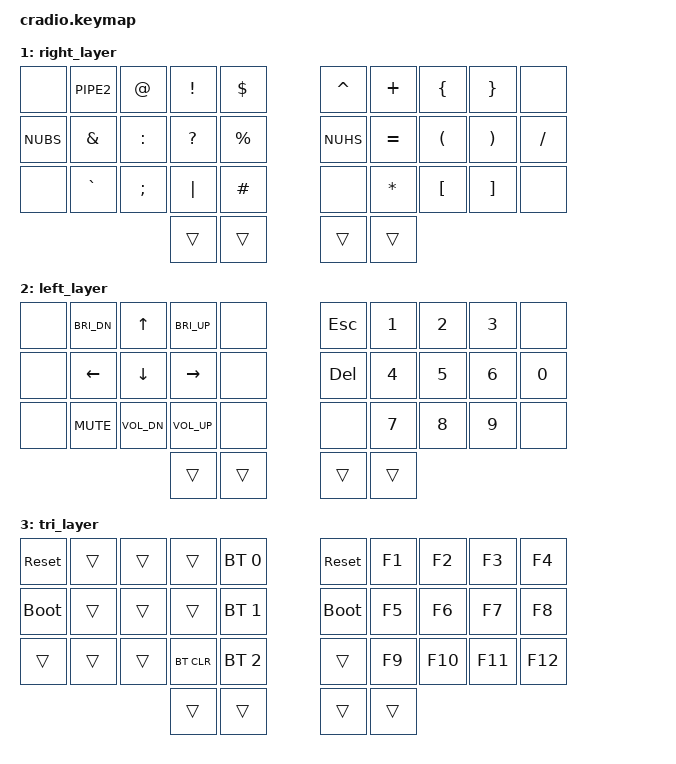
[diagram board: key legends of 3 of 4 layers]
// Copyright (c) 2022 The ZMK Contributors
// SPDX-License-Identifier: MIT

#include <behaviors.dtsi>
#include <dt-bindings/zmk/keys.h>
#include <dt-bindings/zmk/bt.h>

// Home row mods macro
#define HRML(k1,k2,k3,k4) &hml LGUI k1  &hml LALT k2  &hml LSHFT k3  &hml LCTRL k4
#define HRMR(k1,k2,k3,k4) &hmr RCTRL k1  &hmr RSHFT k2  &hmr RALT k3  &hmr RGUI k4

/ {
    behaviors {
        hml: home_row_mod_left {
            compatible = "zmk,behavior-hold-tap";
            #binding-cells = <2>;
            flavor = "balanced";
            tapping-term-ms = <180>;
            quick-tap-ms = <175>;
            require-prior-idle-ms = <150>;
            bindings = <&kp>, <&kp>;
            hold-trigger-key-positions = <0 1 2 3 4 10 11 12 13 14 20 21 22 23 24>; // List of keys on the right side of the keyboard
            hold-trigger-on-release;
        };
        hmr: home_row_mod_right {
            compatible = "zmk,behavior-hold-tap";
            #binding-cells = <2>;
            flavor = "balanced";
            tapping-term-ms = <180>;
            quick-tap-ms = <175>;
            require-prior-idle-ms = <150>;
            bindings = <&kp>, <&kp>;
            hold-trigger-key-positions = <8 6 7 8 9 15 16 17 18 19 25 26 27 28 29>; // List of keys on the right side of the keyboard
            hold-trigger-on-release;
        };
        mt: mod_tap {
            compatible = "zmk,behavior-hold-tap";
            #binding-cells = <2>;
            flavor = "balanced";
            tapping-term-ms = <280>;
            quick-tap-ms = <175>;
            require-prior-idle-ms = <150>;
            bindings = <&mo>, <&kp>;
            hold-trigger-on-release;
        };
    };

    combos {
        compatible = "zmk,combos";
        combo_caps_word {
            key-positions = <12 17>;
            layers = <0>;
            bindings = <&caps_word>;
        };
    };

    conditional_layers {
        compatible = "zmk,conditional-layers";
        tri_layer {
            if-layers = <1 2>;
            then-layer = <3>;
        };
    };

    keymap {
        compatible = "zmk,keymap";
        default_layer {
            bindings = <
        //╭──────────┬──────────┬──────────┬──────────┬──────────╮   ╭──────────┬──────────┬──────────┬──────────┬──────────╮
        //│  B       │  L       │  D       │  W       │  Z       │   │  '       │  F       │  O       │  U       │  J       │
            &kp B      &kp L      &kp D      &kp W      &kp Z          &kp SQT      &kp F      &kp O      &kp U      &kp J
        //├──────────┼──────────┼──────────┼──────────┼──────────┤   ├──────────┼──────────┼──────────┼──────────┼──────────┤
        //│  N       │  R       │  T       │  S       │  G       │   │  Y       │  H       │  A       │  E       │ I      │
            HRML(N,        R,         T,         S)     &kp G          &kp Y      HRMR(H,        A,         E,        I)
        //├──────────┼──────────┼──────────┼──────────┼──────────┤   ├──────────┼──────────┼──────────┼──────────┼──────────┤
        //│  Q       │  X       │  M       │  C       │  V       │   │  K       │  P       │ . >      │ - _      │ , <      │
            &kp Q      &kp X      &kp M      &kp C      &kp V          &kp K      &kp P      &kp DOT  &kp MINUS    &kp COMMA
        //╰──────────┴──────────┴──────────┼──────────┼──────────┤   ├──────────┼──────────┼──────────┴──────────┴──────────╯
                                            &kp TAB    &mt 2 BSPC     &mt 1 SPACE &kp ENTER  
        //                                 ╰──────────┴──────────╯   ╰──────────┴──────────╯
            >;
        };

        right_layer {
            bindings = <
        //╭──────────┬──────────┬──────────┬──────────┬──────────╮   ╭──────────┬──────────┬──────────┬──────────┬──────────╮
        //│          │  |       │  "       │  !       │  $       │   │ ^        │ +        │ {        │ }        │          │
            &none     &kp PIPE2  &kp AT     &kp EXCL   &kp DLLR       &kp CARET  &kp PLUS   &kp LBRC   &kp RBRC   &none
        //├──────────┼──────────┼──────────┼──────────┼──────────┤   ├──────────┼──────────┼──────────┼──────────┼──────────┤
        //│ \        │  &       │  :       │  ?       │  %       │   │ #        │ =        │ (        │ )        │  /       │
            &kp NUBS  &kp AMPS   &kp COLON  &kp QMARK  &kp PRCNT      &kp NUHS   &kp EQUAL  &kp LPAR   &kp RPAR   &kp FSLH
        //├──────────┼──────────┼──────────┼──────────┼──────────┤   ├──────────┼──────────┼──────────┼──────────┼──────────┤
        //│          │  `       │  ;       │  ~       │  £       │   │          │ *        │ [        │ ]        │          │
            &none     &kp GRAVE  &kp SEMI   &kp PIPE   &kp HASH       &none      &kp STAR   &kp LBKT   &kp RBKT   &none
        //╰──────────┴──────────┴──────────┼──────────┼──────────┤   ├──────────┼──────────┼──────────┴──────────┴──────────╯
                                             &trans     &trans        &trans     &trans
        //                                 ╰──────────┴──────────╯   ╰──────────┴──────────╯
            >;
        };

        left_layer {
            bindings = <
        //╭──────────┬──────────┬──────────┬──────────┬──────────╮   ╭──────────┬──────────┬──────────┬──────────┬──────────╮
        //│          │ C_BRI_DN │  UP      │ C_BRI_UP │          │   │  ESC     │  1       │  2       │  3       │          │
            &none    &kp C_BRI_DN &kp UP   &kp C_BRI_UP &none         &kp ESC    &kp N1     &kp N2     &kp N3     &none
        //├──────────┼──────────┼──────────┼──────────┼──────────┤   ├──────────┼──────────┼──────────┼──────────┼──────────┤
        //│          │  LEFT    │  DOWN    │  RIGHT   │          │   │  DEL     │  4       │  5       │  6       │  0       │
            &none     &kp LEFT   &kp DOWN   &kp RIGHT  &none          &kp DEL    &kp N4     &kp N5     &kp N6     &kp N0
        //├──────────┼──────────┼──────────┼──────────┼──────────┤   ├──────────┼──────────┼──────────┼──────────┼──────────┤
        //│          │ C_MUTE   │ C_VOL_UP │ C_VOL_D  │          │   │          │  7       │  8       │  9       │          │
            &none    &kp C_MUTE &kp C_VOL_DN &kp C_VOL_UP  &none      &none      &kp N7     &kp N8     &kp N9     &none
        //╰──────────┴──────────┴──────────┼──────────┼──────────┤   ├──────────┼──────────┼──────────┴──────────┴──────────╯
                                             &trans     &trans         &trans     &trans
        //                                 ╰──────────┴──────────╯   ╰──────────┴──────────╯
            >;
        };

        tri_layer {
            bindings = <
        //╭──────────┬──────────┬──────────┬──────────┬──────────╮   ╭──────────┬──────────┬──────────┬──────────┬──────────╮
        //│ RESET    │          │          │          │PROFILE 0 │   │  RESET   │    F1    │    F2    │    F3    │    F4    │
           &sys_reset  &trans     &trans     &trans    &bt BT_SEL 0   &sys_reset   &kp F1     &kp F2     &kp F3    &kp F4
        //├──────────┼──────────┼──────────┼──────────┼──────────┤   ├──────────┼──────────┼──────────┼──────────┼──────────┤
        //│BOOTLOADER│          │          │          │PROFILE 1 │   │BOOTLOADER│    F5    │    F6    │    F7    │    F8    │
          &bootloader  &trans     &trans     &trans    &bt BT_SEL 1   &bootloader  &kp F5     &kp F6     &kp F7    &kp F8
        //├──────────┼──────────┼──────────┼──────────┼──────────┤   ├──────────┼──────────┼──────────┼──────────┼──────────┤
        //│          │          │          │ CLEAR BT │PROFILE 2 │   │          │    F9    │    F10   │    F11   │    F12   │
            &trans     &trans     &trans    &bt BT_CLR &bt BT_SEL 2    &trans     &kp F9     &kp F10    &kp F11    &kp F12
        //╰──────────┴──────────┴──────────┼──────────┼──────────┤   ├──────────┼──────────┼──────────┴──────────┴──────────╯
                                             &trans     &trans         &trans     &trans
        //                                 ╰──────────┴──────────╯   ╰──────────┴──────────╯
            >;
        };
    };
};
